# ATmega16A register map
Vendor: Atmel; File version: 1.0
CPU: other r0p0, little endian, no MPU, no FPU, 4 interrupt priority bits
Registers are 8-bit, read-write, reset 0x0 unless marked. A register's access mark holds for its fields unless they carry their own. Offsets are from the block's base; [hi:lo] are bit positions.

## TC2 — Timer/Counter, 8-bit Async
Base 0x00800042
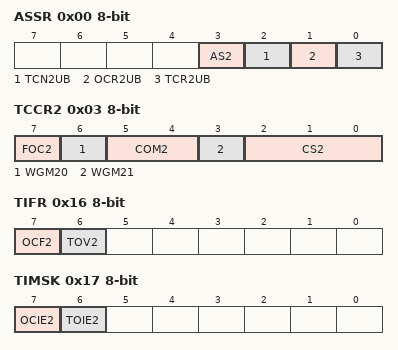
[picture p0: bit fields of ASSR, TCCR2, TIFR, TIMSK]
0x00 ASSR — Asynchronous Status Register
  [3] AS2 — Asynchronous Timer/counter2
  [2] TCN2UB — Timer/Counter2 Update Busy
  [1] OCR2UB — Output Compare Register2 Update Busy
  [0] TCR2UB — Timer/counter Control Register2 Update Busy
0x01 OCR2 — Timer/Counter2 Output Compare Register
  [7:0] OCR2 — Timer/Counter2 Output Compare bits
0x02 TCNT2 — Timer/Counter2
0x03 TCCR2 — Timer/Counter2 Control Register
  [7] FOC2 — Force Output Compare
  [6] WGM20 — Waveform Generation Mode
    0=NORMAL; 1=CTC
  [5:4] COM2 — Compare Output Mode bits
  [3] WGM21 — Waveform Generation Mode
  [2:0] CS2 — Clock Select bits
    0=NO_CLOCK_SOURCE_STOPPED; 1=RUNNING_NO_PRESCALING; 2=RUNNING_CLK_8; 3=RUNNING_CLK_32; 4=RUNNING_CLK_64; 5=RUNNING_CLK_128; 6=RUNNING_CLK_256; 7=RUNNING_CLK_1024
0x0E SFIOR — Special Function IO Register
  [1] PSR2 — Prescaler Reset Timer/Counter2
0x16 TIFR — Timer/Counter Interrupt Flag Register (read-only for debugger)
  [7] OCF2 — Output Compare Flag 2
  [6] TOV2 — Timer/Counter2 Overflow Flag
0x17 TIMSK — Timer/Counter Interrupt Mask register
  [7] OCIE2 — Timer/Counter2 Output Compare Match Interrupt Enable
  [6] TOIE2 — Timer/Counter2 Overflow Interrupt Enable

## TWI — Two Wire Serial Interface
Base 0x00800020
0x00 TWBR — TWI Bit Rate register
  [7:0] TWBR — TWI Bit Rate bits
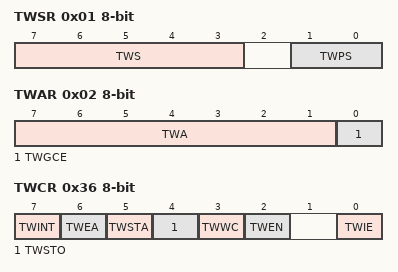
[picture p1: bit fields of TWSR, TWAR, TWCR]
0x01 TWSR — TWI Status Register
  [7:3] TWS — TWI Status
  [1:0] TWPS — TWI Prescaler
    0=1; 1=4; 2=16; 3=64
0x02 TWAR — TWI (Slave) Address register
  [7:1] TWA — TWI (Slave) Address register Bits
  [0] TWGCE — TWI General Call Recognition Enable Bit
0x03 TWDR — TWI Data register
  [7:0] TWD — TWI Data bits
0x36 TWCR — TWI Control Register (read-only for debugger)
  [7] TWINT — TWI Interrupt Flag
  [6] TWEA — TWI Enable Acknowledge Bit
  [5] TWSTA — TWI Start Condition Bit
  [4] TWSTO — TWI Stop Condition Bit
  [3] TWWC — TWI Write Collision Flag
  [2] TWEN — TWI Enable Bit
  [0] TWIE — TWI Interrupt Enable

## USART
Base 0x00800029
0x00 UBRRL — USART Baud Rate Register
  [7:0] UBRR — USART Baud Rate bits
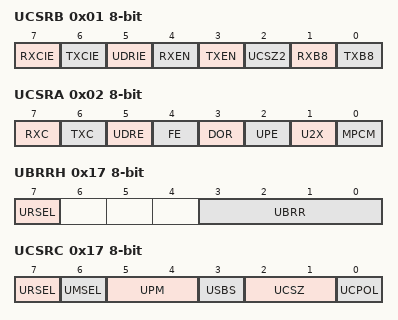
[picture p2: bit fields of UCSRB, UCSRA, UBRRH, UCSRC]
0x01 UCSRB — USART Control and Status Register B
  [7] RXCIE — RX Complete Interrupt Enable
  [6] TXCIE — TX Complete Interrupt Enable
  [5] UDRIE — USART Data register Empty Interrupt Enable
  [4] RXEN — Receiver Enable
  [3] TXEN — Transmitter Enable
  [2] UCSZ2 — Character Size
  [1] RXB8 — Receive Data Bit 8
  [0] TXB8 — Transmit Data Bit 8
0x02 UCSRA — USART Control and Status Register A (read-only for debugger)
  [7] RXC ro — USART Receive Complete
  [6] TXC — USART Transmit Complete
  [5] UDRE ro — USART Data Register Empty
  [4] FE ro — Framing Error
  [3] DOR ro — Data Overrun
  [2] UPE ro — Parity Error
  [1] U2X — Double the USART transmission speed
  [0] MPCM — Multi-processor Communication Mode
0x03 UDR — USART I/O Data Register (write-only for debugger)
  [7:0] UDR — USART I/O Data bits
0x17 UBRRH — USART Baud Rate Register
  [7] URSEL — Register Select
  [3:0] UBRR — USART Baud Rate bits
0x17 UCSRC — USART Control and Status Register C (write-only for debugger)
  [7] URSEL — Register Select
  [6] UMSEL — USART Mode Select
    0=ASYNCHRONOUS_OPERATION; 1=SYNCHRONOUS_OPERATION
  [5:4] UPM — Parity Mode Bits
    0=DISABLED; 2=ENABLED_EVEN_PARITY; 3=ENABLED_ODD_PARITY
  [3] USBS — Stop Bit Select
    0=1_BIT; 1=2_BIT
  [2:1] UCSZ — Character Size
  [0] UCPOL — Clock Polarity

## WDT — Watchdog Timer
Base 0x00800041
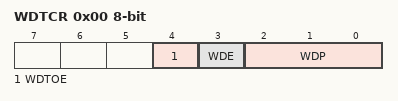
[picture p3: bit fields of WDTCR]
0x00 WDTCR — Watchdog Timer Control Register
  [4] WDTOE — RW
  [3] WDE — Watch Dog Enable
  [2:0] WDP — Watch Dog Timer Prescaler bits
    0=OSCILLATOR_CYCLES_16K; 1=OSCILLATOR_CYCLES_32K; 2=OSCILLATOR_CYCLES_64K; 3=OSCILLATOR_CYCLES_128K; 4=OSCILLATOR_CYCLES_256K; 5=OSCILLATOR_CYCLES_512K; 6=OSCILLATOR_CYCLES_1024K; 7=OSCILLATOR_CYCLES_2048K
